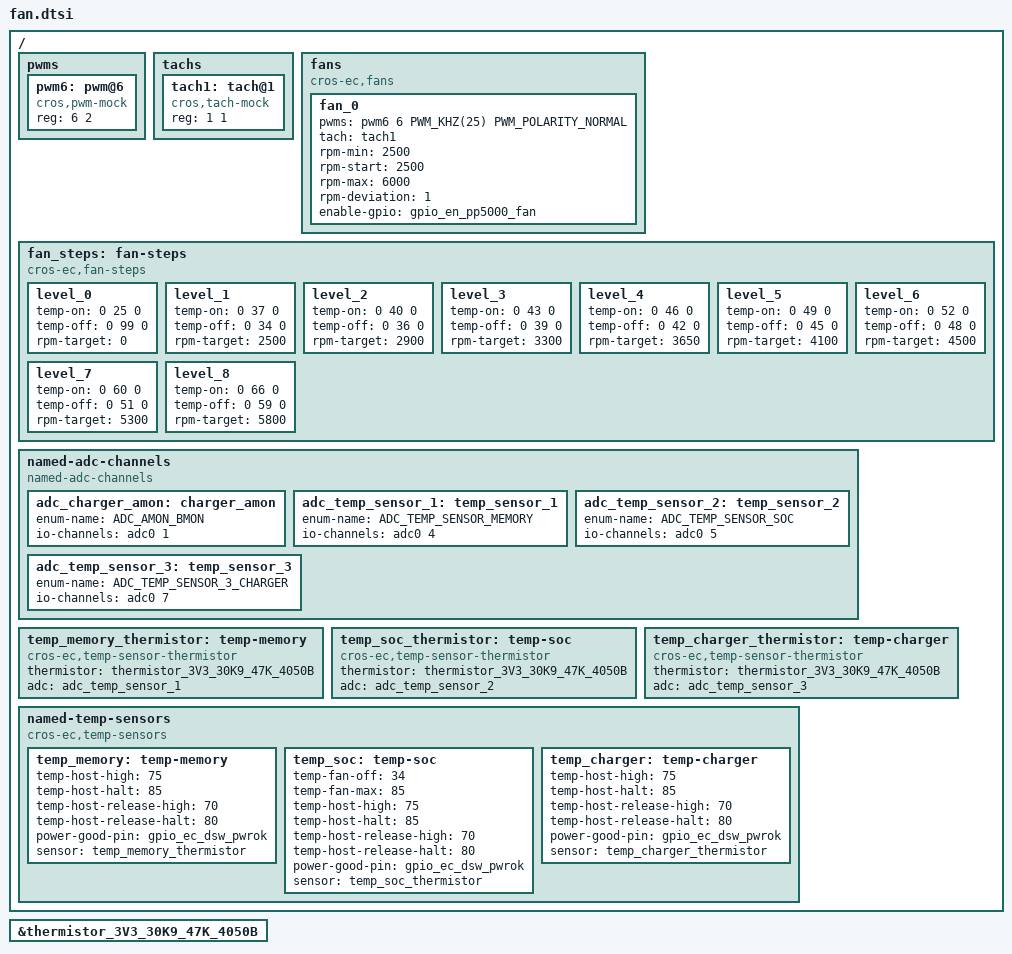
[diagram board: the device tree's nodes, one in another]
/* Copyright 2026 The ChromiumOS Authors
 * Use of this source code is governed by a BSD-style license that can be
 * found in the LICENSE file.
 */

#include <dt-bindings/pwm/pwm.h>
#include <cros/thermistor/thermistor.dtsi>

#include "../baseboard/baseboard.overlay"
#include "../program/brox/juchi/cbi.dtsi"

/ {
	pwms {
		#address-cells = <1>;
		#size-cells = <1>;

		pwm6: pwm@6 {
			compatible = "cros,pwm-mock";
			reg = <6 2>;
			#pwm-cells = <3>;
			status = "okay";
		};
	};

	tachs {
		#address-cells = <1>;
		#size-cells = <1>;

		tach1: tach@1 {
			compatible = "cros,tach-mock";
			reg = <1 1>;
			#tach-cells = <3>;
			status = "okay";
		};
	};

	fans {
		compatible = "cros-ec,fans";
		fan_0 {
			pwms = <&pwm6 6
				PWM_KHZ(25)
				PWM_POLARITY_NORMAL>;
			tach = <&tach1>;
			rpm-min = <2500>;
			rpm-start = <2500>;
			rpm-max = <6000>;
			rpm-deviation = <1>;
			enable-gpio = <&gpio_en_pp5000_fan>;
		};
	};

	fan_steps: fan-steps {
		compatible = "cros-ec,fan-steps";
		level_0 {
			temp-on = <0 25 0>;
			temp-off = <0 99 0>;
			rpm-target = <0>;
		};
		level_1 {
			temp-on = <0 37 0>;
			temp-off = <0 34 0>;
			rpm-target = <2500>;
		};
		level_2 {
			temp-on = <0 40 0>;
			temp-off = <0 36 0>;
			rpm-target = <2900>;
		};
		level_3 {
			temp-on = <0 43 0>;
			temp-off = <0 39 0>;
			rpm-target = <3300>;
		};
		level_4 {
			temp-on = <0 46 0>;
			temp-off = <0 42 0>;
			rpm-target = <3650>;
		};
		level_5 {
			temp-on = <0 49 0>;
			temp-off = <0 45 0>;
			rpm-target = <4100>;
		};
		level_6 {
			temp-on = <0 52 0>;
			temp-off = <0 48 0>;
			rpm-target = <4500>;
		};
		level_7 {
			temp-on = <0 60 0>;
			temp-off = <0 51 0>;
			rpm-target = <5300>;
		};
		level_8 {
			temp-on = <0 66 0>;
			temp-off = <0 59 0>;
			rpm-target = <5800>;
		};
	};

	named-adc-channels {
		compatible = "named-adc-channels";

		adc_charger_amon: charger_amon {
			enum-name = "ADC_AMON_BMON";
			io-channels = <&adc0 1>;
		};
		adc_temp_sensor_1: temp_sensor_1 {
			enum-name = "ADC_TEMP_SENSOR_MEMORY";
			io-channels = <&adc0 4>;
		};
		adc_temp_sensor_2: temp_sensor_2 {
			enum-name = "ADC_TEMP_SENSOR_SOC";
			io-channels = <&adc0 5>;
		};
		adc_temp_sensor_3: temp_sensor_3 {
			enum-name = "ADC_TEMP_SENSOR_3_CHARGER";
			io-channels = <&adc0 7>;
		};
	};

	temp_memory_thermistor: temp-memory {
		compatible = "cros-ec,temp-sensor-thermistor";
		thermistor = <&thermistor_3V3_30K9_47K_4050B>;
		adc = <&adc_temp_sensor_1>;
	};

	temp_soc_thermistor: temp-soc {
		compatible = "cros-ec,temp-sensor-thermistor";
		thermistor = <&thermistor_3V3_30K9_47K_4050B>;
		adc = <&adc_temp_sensor_2>;
	};

	temp_charger_thermistor: temp-charger {
		compatible = "cros-ec,temp-sensor-thermistor";
		thermistor = <&thermistor_3V3_30K9_47K_4050B>;
		adc = <&adc_temp_sensor_3>;
	};

	named-temp-sensors {
		compatible = "cros-ec,temp-sensors";
		temp_memory: temp-memory {
			temp-host-high = <75>;
			temp-host-halt = <85>;
			temp-host-release-high = <70>;
			temp-host-release-halt = <80>;
			power-good-pin = <&gpio_ec_dsw_pwrok>;
			sensor = <&temp_memory_thermistor>;
		};

		temp_soc: temp-soc {
			temp-fan-off = <34>;
			temp-fan-max = <85>;
			temp-host-high = <75>;
			temp-host-halt = <85>;
			temp-host-release-high = <70>;
			temp-host-release-halt = <80>;
			power-good-pin = <&gpio_ec_dsw_pwrok>;
			sensor = <&temp_soc_thermistor>;
		};

		temp_charger: temp-charger {
			temp-host-high = <75>;
			temp-host-halt = <85>;
			temp-host-release-high = <70>;
			temp-host-release-halt = <80>;
			power-good-pin = <&gpio_ec_dsw_pwrok>;
			sensor = <&temp_charger_thermistor>;
		};
	};

};

&thermistor_3V3_30K9_47K_4050B {
	status = "okay";
};
